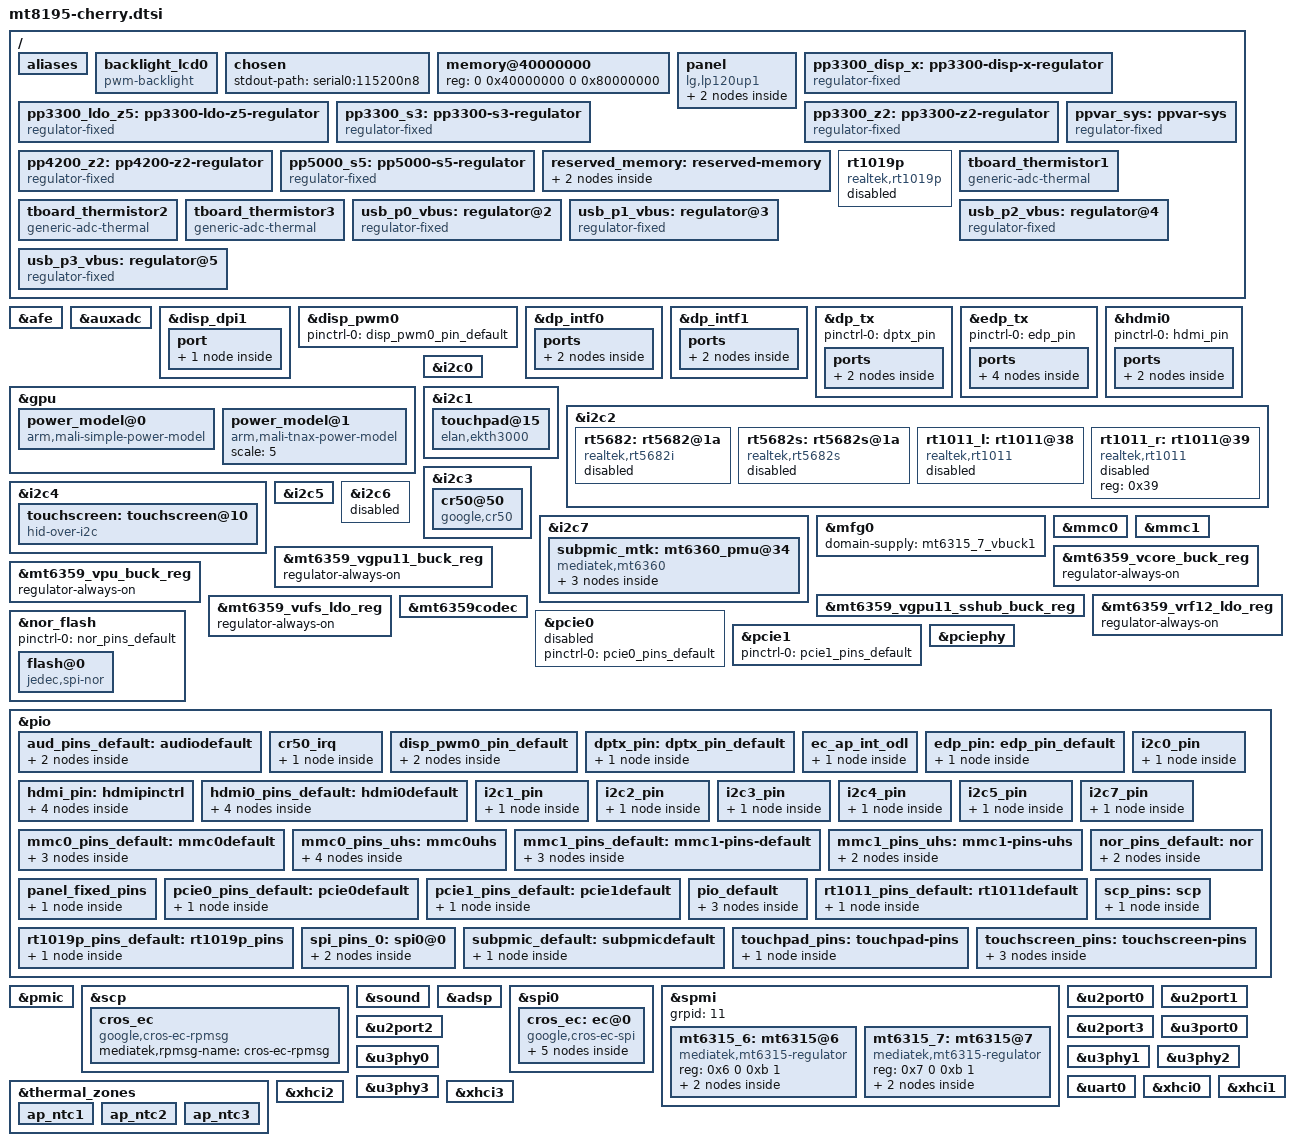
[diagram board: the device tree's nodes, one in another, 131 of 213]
// SPDX-License-Identifier: (GPL-2.0 OR MIT)
/*
 * Copyright (C) 2021 MediaTek Inc.
 */
/dts-v1/;
#include <dt-bindings/gpio/gpio.h>
#include "mt8195.dtsi"
#include "mt6359.dtsi"

/ {
	aliases {
		i2c0 = &i2c0;
		i2c1 = &i2c1;
		i2c2 = &i2c2;
		i2c3 = &i2c3;
		i2c4 = &i2c4;
		i2c5 = &i2c5;
		i2c6 = &i2c6;
		i2c7 = &i2c7;
		mmc0 = &mmc0;
		mmc1 = &mmc1;
		serial0 = &uart0;
	};

	backlight_lcd0: backlight_lcd0 {
		compatible = "pwm-backlight";
		pwms = <&disp_pwm0 0 500000>;
		power-supply = <&ppvar_sys>;
		enable-gpios = <&pio 82 GPIO_ACTIVE_HIGH>;
		brightness-levels = <0 1023>;
		num-interpolated-steps = <1023>;
		default-brightness-level = <576>;
		status = "okay";
	};

	chosen {
		stdout-path = "serial0:115200n8";
	};

	memory@40000000 {
		device_type = "memory";
		reg = <0 0x40000000 0 0x80000000>;
	};

	panel: panel {
		compatible = "lg,lp120up1";
		power-supply = <&pp3300_disp_x>;
		backlight = <&backlight_lcd0>;

		port {
			panel_in: endpoint {
				remote-endpoint = <&edp_out>;
			};
		};
	};

	pp3300_disp_x: pp3300-disp-x-regulator {
		compatible = "regulator-fixed";
		regulator-name = "pp3300_disp_x";
		enable-active-high;
		gpio = <&pio 55 GPIO_ACTIVE_HIGH>;
		pinctrl-names = "default";
		pinctrl-0 = <&panel_fixed_pins>;
		vin-supply = <&pp3300_z2>;
	};

	/* system wide LDO 3.3V power rail */
	pp3300_ldo_z5: pp3300-ldo-z5-regulator {
		compatible = "regulator-fixed";
		regulator-name = "pp3300_ldo_z5";
		regulator-always-on;
		regulator-boot-on;
		regulator-min-microvolt = <3300000>;
		regulator-max-microvolt = <3300000>;
		vin-supply = <&ppvar_sys>;
	};

	/* separately switched 3.3V power rail */
	pp3300_s3: pp3300-s3-regulator {
		compatible = "regulator-fixed";
		regulator-name = "pp3300_s3";
		/* automatically sequenced by PMIC EXT_PMIC_EN2 */
		regulator-always-on;
		regulator-boot-on;
		vin-supply = <&pp3300_z2>;
	};

	/* system wide 3.3V power rail */
	pp3300_z2: pp3300-z2-regulator {
		compatible = "regulator-fixed";
		regulator-name = "pp3300_z2";
		/* EN pin tied to pp4200_z2, which is controlled by EC */
		regulator-always-on;
		regulator-boot-on;
		regulator-min-microvolt = <3300000>;
		regulator-max-microvolt = <3300000>;
		vin-supply = <&ppvar_sys>;
	};

	/* system wide 4.2V power rail */
	pp4200_z2: pp4200-z2-regulator {
		compatible = "regulator-fixed";
		regulator-name = "pp4200_z2";
		/* controlled by EC */
		regulator-always-on;
		regulator-boot-on;
		regulator-min-microvolt = <4200000>;
		regulator-max-microvolt = <4200000>;
		vin-supply = <&ppvar_sys>;
	};

	/* system wide switching 5.0V power rail */
	pp5000_s5: pp5000-s5-regulator {
		compatible = "regulator-fixed";
		regulator-name = "pp5000_s5";
		/* controlled by EC */
		regulator-always-on;
		regulator-boot-on;
		regulator-min-microvolt = <5000000>;
		regulator-max-microvolt = <5000000>;
		vin-supply = <&ppvar_sys>;
	};

	/* system wide semi-regulated power rail from battery or USB */
	ppvar_sys: ppvar-sys {
		compatible = "regulator-fixed";
		regulator-name = "ppvar_sys";
		regulator-always-on;
		regulator-boot-on;
	};

	reserved_memory: reserved-memory {
		#address-cells = <2>;
		#size-cells = <2>;
		ranges;

		scp_mem_reserved: scp_mem_region {
			compatible = "shared-dma-pool";
			reg = <0 0x50000000 0 0x2900000>;
			no-map;
		};

		snd_dma_mem_reserved: snd_dma_mem_region {
			compatible = "shared-dma-pool";
			reg = <0 0x60D80000 0 0x0100000>;
			no-map;
		};
	};

	rt1019p: rt1019p {
		compatible = "realtek,rt1019p";
		pinctrl-names = "default";
		pinctrl-0 = <&rt1019p_pins_default>;
		sdb-gpios = <&pio 100 GPIO_ACTIVE_HIGH>;
		status = "disabled";
	};

	tboard_thermistor1: tboard_thermistor1 {
		compatible = "generic-adc-thermal";
		#thermal-sensor-cells = <0>;
		io-channels = <&auxadc 0>;
		io-channel-names = "sensor-channel";
		temperature-lookup-table = <    (-5000) 1485
                                                0 1406
                                                5000 1317
                                                10000 1219
                                                15000 1115
                                                20000 1007
                                                25000 900
                                                30000 796
                                                35000 697
                                                40000 605
                                                45000 523
                                                50000 449
                                                55000 384
                                                60000 327
                                                65000 279
                                                70000 237
                                                75000 202
                                                80000 172
                                                85000 147
                                                90000 125
                                                95000 107
                                                100000 92
                                                105000 79
                                                110000 68
                                                115000 59
                                                120000 51
                                                125000 44>;
	};

	tboard_thermistor2: tboard_thermistor2 {
		compatible = "generic-adc-thermal";
		#thermal-sensor-cells = <0>;
		io-channels = <&auxadc 0>;
		io-channel-names = "sensor-channel";
		temperature-lookup-table = <    (-5000) 1485
                                                0 1406
                                                5000 1317
                                                10000 1219
                                                15000 1115
                                                20000 1007
                                                25000 900
                                                30000 796
                                                35000 697
                                                40000 605
                                                45000 523
                                                50000 449
                                                55000 384
                                                60000 327
                                                65000 279
                                                70000 237
                                                75000 202
                                                80000 172
                                                85000 147
                                                90000 125
                                                95000 107
                                                100000 92
                                                105000 79
                                                110000 68
                                                115000 59
                                                120000 51
                                                125000 44>;
	};

	tboard_thermistor3: tboard_thermistor3 {
		compatible = "generic-adc-thermal";
		#thermal-sensor-cells = <0>;
		io-channels = <&auxadc 0>;
		io-channel-names = "sensor-channel";
		temperature-lookup-table = <    (-5000) 1485
                                                0 1406
                                                5000 1317
                                                10000 1219
                                                15000 1115
                                                20000 1007
                                                25000 900
                                                30000 796
                                                35000 697
                                                40000 605
                                                45000 523
                                                50000 449
                                                55000 384
                                                60000 327
                                                65000 279
                                                70000 237
                                                75000 202
                                                80000 172
                                                85000 147
                                                90000 125
                                                95000 107
                                                100000 92
                                                105000 79
                                                110000 68
                                                115000 59
                                                120000 51
                                                125000 44>;
	};

	usb_p0_vbus: regulator@2 {
		compatible = "regulator-fixed";
		regulator-name = "vbus0";
		regulator-min-microvolt = <5000000>;
		regulator-max-microvolt = <5000000>;
		enable-active-high;
		regulator-always-on;
	};

	usb_p1_vbus: regulator@3 {
		compatible = "regulator-fixed";
		regulator-name = "vbus1";
		regulator-min-microvolt = <5000000>;
		regulator-max-microvolt = <5000000>;
		enable-active-high;
		regulator-always-on;
	};

	usb_p2_vbus: regulator@4 {
		compatible = "regulator-fixed";
		regulator-name = "vbus2";
		regulator-min-microvolt = <5000000>;
		regulator-max-microvolt = <5000000>;
		enable-active-high;
		regulator-always-on;
	};

	usb_p3_vbus: regulator@5 {
		compatible = "regulator-fixed";
		regulator-name = "vbus3";
		regulator-min-microvolt = <5000000>;
		regulator-max-microvolt = <5000000>;
		enable-active-high;
		regulator-always-on;
	};
};

&afe {
	memory-region = <&snd_dma_mem_reserved>;
	mediatek,etdm-in2-cowork-source = <2>;
	mediatek,etdm-out2-cowork-source = <0>;
	status = "okay";
};

&auxadc {
	status = "okay";
};

&disp_dpi1 {
	port {
		dpi1_out: endpoint@0 {
			remote-endpoint = <&hdmi0_in>;
		};
	};
};

&disp_pwm0 {
	status = "okay";
	pinctrl-names = "default";
	pinctrl-0 = <&disp_pwm0_pin_default>;
};

&dp_intf0 {
	status = "okay";
	ports {
		port {
			dp_intf0_out: endpoint {
				remote-endpoint = <&edp_in>;
			};
		};
	};
};

&dp_intf1 {
	status = "okay";
	ports {
		port {
			dp_intf1_out: endpoint {
				remote-endpoint = <&dptx_in>;
			};
		};
	};
};

&dp_tx {
	pinctrl-names = "default";
	pinctrl-0 = <&dptx_pin>;
	status = "okay";

	ports {
		#address-cells = <1>;
		#size-cells = <0>;
		port@0 {
			reg = <0>;
			dptx_in: endpoint {
			remote-endpoint = <&dp_intf1_out>;
			};
		};
	};
};

&edp_tx {
	pinctrl-names = "default";
	pinctrl-0 = <&edp_pin>;
	status = "okay";

	ports {
		#address-cells = <1>;
		#size-cells = <0>;
		port@0 {
			reg = <0>;
			edp_in: endpoint {
			remote-endpoint = <&dp_intf0_out>;
			};
		};
		port@1 {
			reg = <1>;
			edp_out: endpoint {
				remote-endpoint = <&panel_in>;
			};
		};
	};
};

&gpu {
	supply-names = "mali","mali_sram";
	mali-supply = <&mt6315_7_vbuck1>;
	mali_sram-supply = <&mt6359_vsram_others_ldo_reg>;
	operating-points-v2 = <&gpu_opp_table>;
	power_model@0 {
		compatible = "arm,mali-simple-power-model";
		static-coefficient = <162868>;
		dynamic-coefficient = <2649>;
		ts = <(-199560) 37873 (-665) 9>;
		thermal-zone = "soc_max";
	};
	power_model@1 {
		compatible = "arm,mali-tnax-power-model";
		scale = <5>;
	};
};

&hdmi0 {
	pinctrl-names = "default";
	pinctrl-0 = <&hdmi_pin>;
	ports {
		#address-cells = <1>;
		#size-cells = <0>;
		port@0 {
			reg = <0>;
			hdmi0_in: endpoint {
				remote-endpoint = <&dpi1_out>;
			};
		};
	};
};

&i2c0 {
	clock-frequency = <400000>;
	pinctrl-names = "default";
	pinctrl-0 = <&i2c0_pin>;
};

&i2c1 {
	status = "okay";
	clock-frequency = <400000>;
	pinctrl-names = "default";
	pinctrl-0 = <&i2c1_pin>;
	i2c-scl-internal-delay-ns = <12500>;

	touchpad@15 {
		compatible = "elan,ekth3000";
		reg = <0x15>;

		pinctrl-names = "default";
		pinctrl-0 = <&touchpad_pins>;

		interrupt-parent = <&pio>;
		interrupts = <6 IRQ_TYPE_LEVEL_LOW>;

		vcc-supply = <&pp3300_s3>;

		wakeup-source;
	};
};

&i2c2 {
	status = "okay";
	clock-frequency = <400000>;
	pinctrl-names = "default";
	pinctrl-0 = <&i2c2_pin>;

	rt5682: rt5682@1a {
		compatible = "realtek,rt5682i";
		reg = <0x1a>;
		interrupt-parent = <&pio>;
		interrupts = <89 IRQ_TYPE_EDGE_BOTH>;
		realtek,jd-src = <1>;
		realtek,btndet-delay = <16>;

		AVDD-supply = <&mt6359_vio18_ldo_reg>;
		MICVDD-supply = <&pp3300_z2>;
		VBAT-supply = <&pp3300_ldo_z5>;
		status = "disabled";
	};

	rt5682s: rt5682s@1a {
		compatible = "realtek,rt5682s";
		reg = <0x1a>;
		interrupt-parent = <&pio>;
		interrupts = <89 IRQ_TYPE_EDGE_BOTH>;
		realtek,jd-src = <1>;
		AVDD-supply = <&mt6359_vio18_ldo_reg>;
		MICVDD-supply = <&pp3300_z2>;
		status = "disabled";
	};

	rt1011_l: rt1011@38 {
		compatible = "realtek,rt1011";
		reg = <0x38>;
		pinctrl-names = "default";
		pinctrl-0 = <&rt1011_pins_default>;
		status = "disabled";
	};

	rt1011_r: rt1011@39 {
		compatible = "realtek,rt1011";
		reg = <0x39>;
		status = "disabled";
	};
};

&i2c3 {
	status = "okay";
	clock-frequency = <400000>;
	pinctrl-names = "default";
	pinctrl-0 = <&i2c3_pin>;

	cr50@50 {
		compatible = "google,cr50";
		reg = <0x50>;
		interrupt-parent = <&pio>;
		interrupts = <88 IRQ_TYPE_EDGE_FALLING>;
		pinctrl-names = "default";
		pinctrl-0 = <&cr50_irq>;
	};
};

&i2c4 {
	status = "okay";
	clock-frequency = <400000>;
	pinctrl-names = "default";
	pinctrl-0 = <&i2c4_pin>;

	touchscreen: touchscreen@10 {
		compatible = "hid-over-i2c";
		reg = <0x10>;
		interrupt-parent = <&pio>;
		interrupts = <92 IRQ_TYPE_LEVEL_LOW>;

		pinctrl-names = "default";
		pinctrl-0 = <&touchscreen_pins>;

		post-power-on-delay-ms = <10>;
		hid-descr-addr = <0x0001>;

		vdd-supply = <&pp3300_s3>;
	};
};

&i2c5 {
	status = "okay";
	clock-frequency = <400000>;
	pinctrl-names = "default";
	pinctrl-0 = <&i2c5_pin>;
};

&i2c6 {
	status = "disabled";
};

&i2c7 {
	status = "okay";
	clock-frequency = <400000>;
	pinctrl-names = "default";
	pinctrl-0 = <&i2c7_pin>;

	#address-cells = <1>;
	#size-cells = <0>;

	subpmic_mtk: mt6360_pmu@34 {
		#interrupt-cells = <2>;
		status = "ok";
		compatible = "mediatek,mt6360";
		reg = <0x34>;
		wakeup-source;
		interrupt-controller;

		pinctrl-names = "default";
		pinctrl-0 = <&subpmic_default>;

		interrupt-parent = <&pio>;
		interrupts = <130 IRQ_TYPE_EDGE_FALLING>;
		interrupt-names = "IRQB";

		subpmic_mtk_regulator: regulator {
			compatible = "mediatek,mt6360_ldo";
			mt_pmic_vfp_ldo_reg: ldo1 {
				regulator-compatible = "LDO1";
				regulator-name = "mt6360,ldo1";
				regulator-min-microvolt = <3000000>;
				regulator-max-microvolt = <3600000>;
				regulator-allowed-modes = <0 2>;
				regulator-always-on;
			};
			mt_pmic_vtp_ldo_reg: ldo2 {
				regulator-compatible = "LDO2";
				regulator-name = "vtp";
				regulator-min-microvolt = <1200000>;
				regulator-max-microvolt = <3600000>;
				regulator-allowed-modes = <0 2>;
			};
		};
	};
};

&mfg0 {
	domain-supply = <&mt6315_7_vbuck1>;
};

&mmc0 {
	status = "okay";
	pinctrl-names = "default", "state_uhs";
	pinctrl-0 = <&mmc0_pins_default>;
	pinctrl-1 = <&mmc0_pins_uhs>;
	bus-width = <8>;
	max-frequency = <200000000>;
	cap-mmc-highspeed;
	mmc-hs200-1_8v;
	mmc-hs400-1_8v;
	cap-mmc-hw-reset;
	no-sdio;
	no-sd;
	hs400-ds-delay = <0x14c11>;
	vmmc-supply = <&mt6359_vemc_1_ldo_reg>;
	vqmmc-supply = <&mt6359_vufs_ldo_reg>;
	non-removable;
};

&mmc1 {
	status = "okay";
	pinctrl-names = "default", "state_uhs";
	pinctrl-0 = <&mmc1_pins_default>;
	pinctrl-1 = <&mmc1_pins_uhs>;
	bus-width = <4>;
	max-frequency = <200000000>;
	cap-sd-highspeed;
	sd-uhs-sdr50;
	sd-uhs-sdr104;
	no-mmc;
	no-sdio;
	cd-gpios = <&pio 54 GPIO_ACTIVE_LOW>;
	vmmc-supply = <&mt_pmic_vmch_ldo_reg>;
	vqmmc-supply = <&mt_pmic_vmc_ldo_reg>;
};

/* for CPU-L */
&mt6359_vcore_buck_reg {
	regulator-always-on;
};

/* for CORE */
&mt6359_vgpu11_buck_reg {
	regulator-always-on;
};

&mt6359_vgpu11_sshub_buck_reg {
	regulator-always-on;
	regulator-min-microvolt = <550000>;
	regulator-max-microvolt = <550000>;
};

/* for CORE SRAM */
&mt6359_vpu_buck_reg {
	regulator-always-on;
};

&mt6359_vrf12_ldo_reg {
	regulator-always-on;
};

&mt6359_vufs_ldo_reg {
	regulator-always-on;
};

&mt6359codec {
	mediatek,dmic-mode = <1>; /* one-wire */
	mediatek,mic-type-0 = <2>; /* DMIC */
};

&nor_flash {
	status = "okay";
	pinctrl-names = "default";
	pinctrl-0 = <&nor_pins_default>;

	flash@0 {
		compatible = "jedec,spi-nor";
		reg = <0>;
		spi-max-frequency = <52000000>;
		spi-rx-bus-width = <2>;
		spi-tx-bus-width = <2>;
	};
};

&pcie0 {
	pinctrl-names = "default";
	pinctrl-0 = <&pcie0_pins_default>;
	status = "disabled";
};

&pcie1 {
	pinctrl-names = "default";
	pinctrl-0 = <&pcie1_pins_default>;
	status = "okay";
};

&pciephy {
	status = "okay";
};

&pio {
	pinctrl-names = "default";
	pinctrl-0 = <&pio_default>;

	/* 144 lines */
	gpio-line-names =
		"I2S_SPKR_MCLK",
		"I2S_SPKR_DATAIN",
		"I2S_SPKR_LRCK",
		"I2S_SPKR_BCLK",
		"EC_AP_INT_ODL",
		/*
		 * AP_FLASH_WP_L is crossystem ABI. Schematics
		 * call it AP_FLASH_WP_ODL.
		 */
		"AP_FLASH_WP_L",
		"TCHPAD_INT_ODL",
		"EDP_HPD_1V8",
		"AP_I2C_CAM_SDA",
		"AP_I2C_CAM_SCL",
		"AP_I2C_TCHPAD_SDA_1V8",
		"AP_I2C_TCHPAD_SCL_1V8",
		"AP_I2C_AUD_SDA",
		"AP_I2C_AUD_SCL",
		"AP_I2C_TPM_SDA_1V8",
		"AP_I2C_TPM_SCL_1V8",
		"AP_I2C_TCHSCR_SDA_1V8",
		"AP_I2C_TCHSCR_SCL_1V8",
		"EC_AP_HPD_OD",
		"",
		"PCIE_NVME_RST_L",
		"PCIE_NVME_CLKREQ_ODL",
		"PCIE_RST_1V8_L",
		"PCIE_CLKREQ_1V8_ODL",
		"PCIE_WAKE_1V8_ODL",
		"CLK_24M_CAM0",
		"CAM1_SEN_EN",
		"AP_I2C_PWR_SCL_1V8",
		"AP_I2C_PWR_SDA_1V8",
		"AP_I2C_MISC_SCL",
		"AP_I2C_MISC_SDA",
		"EN_PP5000_HDMI_X",
		"AP_HDMITX_HTPLG",
		"",
		"AP_HDMITX_SCL_1V8",
		"AP_HDMITX_SDA_1V8",
		"AP_RTC_CLK32K",
		"AP_EC_WATCHDOG_L",
		"SRCLKENA0",
		"SRCLKENA1",
		"PWRAP_SPI0_CS_L",
		"PWRAP_SPI0_CK",
		"PWRAP_SPI0_MOSI",
		"PWRAP_SPI0_MISO",
		"SPMI_SCL",
		"SPMI_SDA",
		"",
		"",
		"",
		"I2S_HP_DATAIN",
		"I2S_HP_MCLK",
		"I2S_HP_BCK",
		"I2S_HP_LRCK",
		"I2S_HP_DATAOUT",
		"SD_CD_ODL",
		"EN_PP3300_DISP_X",
		"TCHSCR_RST_1V8_L",
		"TCHSCR_REPORT_DISABLE",
		"EN_PP3300_WLAN_X",
		"BT_KILL_1V8_L",
		"I2S_SPKR_DATAOUT",
		"WIFI_KILL_1V8_L",
		"BEEP_ON",
		"SCP_I2C_SENSOR_SCL_1V8",
		"SCP_I2C_SENSOR_SDA_1V8",
		"",
		"",
		"",
		"",
		"AUD_CLK_MOSI",
		"AUD_SYNC_MOSI",
		"AUD_DAT_MOSI0",
		"AUD_DAT_MOSI1",
		"AUD_DAT_MISO0",
		"AUD_DAT_MISO1",
		"AUD_DAT_MISO2",
		"SCP_VREQ_VAO",
		"AP_SPI_GSC_TPM_CLK",
		"AP_SPI_GSC_TPM_MOSI",
		"AP_SPI_GSC_TPM_CS_L",
		"AP_SPI_GSC_TPM_MISO",
		"EN_PP1000_CAM_X",
		"AP_EDP_BKLTEN",
		"",
		"USB3_HUB_RST_L",
		"",
		"WLAN_ALERT_ODL",
		"EC_IN_RW_ODL",
		"GSC_AP_INT_ODL",
		"HP_INT_ODL",
		"CAM0_RST_L",
		"CAM1_RST_L",
		"TCHSCR_INT_1V8_L",
		"CAM1_DET_L",
		"RST_ALC1011_L",
		"",
		"",
		"BL_PWM_1V8",
		"UART_AP_TX_DBG_RX",
		"UART_DBG_TX_AP_RX",
		"EN_SPKR",
		"AP_EC_WARM_RST_REQ",
		"UART_SCP_TX_DBGCON_RX",
		"UART_DBGCON_TX_SCP_RX",
		"",
		"",
		"KPCOL0",
		"",
		"MT6315_GPU_INT",
		"MT6315_PROC_BC_INT",
		"SD_CMD",
		"SD_CLK",
		"SD_DAT0",
		"SD_DAT1",
		"SD_DAT2",
		"SD_DAT3",
		"EMMC_DAT7",
		"EMMC_DAT6",
		"EMMC_DAT5",
		"EMMC_DAT4",
		"EMMC_RSTB",
		"EMMC_CMD",
		"EMMC_CLK",
		"EMMC_DAT3",
		"EMMC_DAT2",
		"EMMC_DAT1",
		"EMMC_DAT0",
		"EMMC_DSL",
		"",
		"",
		"MT6360_INT_ODL",
		"SCP_JTAG0_TRSTN",
		"AP_SPI_EC_CS_L",
		"AP_SPI_EC_CLK",
		"AP_SPI_EC_MOSI",
		"AP_SPI_EC_MISO",
		"SCP_JTAG0_TMS",
		"SCP_JTAG0_TCK",
		"SCP_JTAG0_TDO",
		"SCP_JTAG0_TDI",
		"AP_SPI_FLASH_CS_L",
		"AP_SPI_FLASH_CLK",
		"AP_SPI_FLASH_MOSI",
		"AP_SPI_FLASH_MISO";

	aud_pins_default: audiodefault {
		pins_cmd_dat {
		    pinmux = <PINMUX_GPIO69__FUNC_AUD_CLK_MOSI>,
			     <PINMUX_GPIO70__FUNC_AUD_SYNC_MOSI>,
			     <PINMUX_GPIO71__FUNC_AUD_DAT_MOSI0>,
			     <PINMUX_GPIO72__FUNC_AUD_DAT_MOSI1>,
			     <PINMUX_GPIO73__FUNC_AUD_DAT_MISO0>,
			     <PINMUX_GPIO74__FUNC_AUD_DAT_MISO1>,
			     <PINMUX_GPIO75__FUNC_AUD_DAT_MISO2>,
			     <PINMUX_GPIO0__FUNC_TDMIN_MCK>,
			     <PINMUX_GPIO1__FUNC_TDMIN_DI>,
			     <PINMUX_GPIO2__FUNC_TDMIN_LRCK>,
			     <PINMUX_GPIO3__FUNC_TDMIN_BCK>,
			     <PINMUX_GPIO60__FUNC_I2SO2_D0>,
			     <PINMUX_GPIO49__FUNC_I2SIN_D0>,
			     <PINMUX_GPIO50__FUNC_I2SO1_MCK>,
			     <PINMUX_GPIO51__FUNC_I2SO1_BCK>,
			     <PINMUX_GPIO52__FUNC_I2SO1_WS>,
			     <PINMUX_GPIO53__FUNC_I2SO1_D0>;
		};

		pins_jack {
			pinmux = <PINMUX_GPIO89__FUNC_GPIO89>;
			input-enable;
			bias-pull-up = <MTK_PUPD_SET_R1R0_01>;
		};
	};

	cr50_irq: cr50_irq {
		pins_bus {
			pinmux = <PINMUX_GPIO88__FUNC_GPIO88>;
			input-enable;
		};
	};

	disp_pwm0_pin_default: disp_pwm0_pin_default {
		pins1 {
			pinmux = <PINMUX_GPIO82__FUNC_GPIO82>;
		};
		pins2 {
			pinmux = <PINMUX_GPIO97__FUNC_DISP_PWM0>;
		};
	};

	dptx_pin: dptx_pin_default {
		pins_cmd_dat1 {
			pinmux = <PINMUX_GPIO18__FUNC_DP_TX_HPD>;
			bias-pull-up;
		};
	};

	ec_ap_int_odl: ec_ap_int_odl {
		pins1 {
			pinmux = <PINMUX_GPIO4__FUNC_GPIO4>;
			input-enable;
			bias-pull-up = <MTK_PUPD_SET_R1R0_01>;
		};
	};

	edp_pin: edp_pin_default {
		pins_cmd_dat {
			pinmux = <PINMUX_GPIO7__FUNC_EDP_TX_HPD>;
			bias-pull-up;
		};
	};

	hdmi_pin: hdmipinctrl {
		hdmi_hotplug {
			pinmux = <PINMUX_GPIO32__FUNC_HDMITX20_HTPLG>;
			bias-disable;
			input-enable;
		};
		hdmi_ddc {
			pinmux = <PINMUX_GPIO34__FUNC_HDMITX20_SCL>,
				 <PINMUX_GPIO35__FUNC_HDMITX20_SDA>;
			mediatek,drive-strength-adv = <0>;
			drive-strength = <MTK_DRIVE_10mA>;
		};
		hdmi_cec {
			pinmux = <PINMUX_GPIO33__FUNC_HDMITX20_CEC>;
			bias-disable;
		};
		hdmi_5vctrl {
			pinmux = <PINMUX_GPIO31__FUNC_GPIO31>;
			slew-rate = <1>;
			output-high;
		};
	};

	hdmi0_pins_default: hdmi0default {
		hdmirx_hpd {
			pinmux = <PINMUX_GPIO27__FUNC_HDMIRX20_HTPLG>;
		};
		hdmirx_5v {
			pinmux = <PINMUX_GPIO28__FUNC_HDMIRX20_PWR5V>;
			bias-disable;
		};
		hdmirx_scl {
			pinmux = <PINMUX_GPIO29__FUNC_HDMIRX20_SCL>;
		};
		hdmirx_sda {
			pinmux = <PINMUX_GPIO30__FUNC_HDMIRX20_SDA>;
			mediatek,drive-strength-adv = <0>;
			drive-strength = <MTK_DRIVE_10mA>;
		};
	};

	i2c0_pin: i2c0_pin {
		pins_bus {
			pinmux = <PINMUX_GPIO8__FUNC_SDA0>,
				 <PINMUX_GPIO9__FUNC_SCL0>;
			bias-disable;
			mediatek,drive-strength-adv = <7>;
		};
	};

	i2c1_pin: i2c1_pin {
		pins_bus {
			pinmux = <PINMUX_GPIO10__FUNC_SDA1>,
				 <PINMUX_GPIO11__FUNC_SCL1>;
			bias-pull-up;
			mediatek,rsel = <7>;
			mediatek,drive-strength-adv = <7>;
		};
	};

	i2c2_pin: i2c2_pin {
		pins_bus {
			pinmux = <PINMUX_GPIO12__FUNC_SDA2>,
				 <PINMUX_GPIO13__FUNC_SCL2>;
			bias-disable;
			mediatek,drive-strength-adv = <7>;
		};
	};

	i2c3_pin: i2c3_pin {
		pins_bus {
			pinmux = <PINMUX_GPIO14__FUNC_SDA3>,
				 <PINMUX_GPIO15__FUNC_SCL3>;
			bias-pull-up;
			mediatek,rsel = <7>;
			mediatek,drive-strength-adv = <7>;
		};
	};

	i2c4_pin: i2c4_pin {
		pins_bus {
			pinmux = <PINMUX_GPIO16__FUNC_SDA4>,
				 <PINMUX_GPIO17__FUNC_SCL4>;
			bias-pull-up;
			mediatek,rsel = <7>;
			mediatek,drive-strength-adv = <0>;
			drive-strength = <MTK_DRIVE_4mA>;
		};
	};

	i2c5_pin: i2c5_pin {
		pins_bus {
			pinmux = <PINMUX_GPIO29__FUNC_SCL5>,
				 <PINMUX_GPIO30__FUNC_SDA5>;
			bias-disable;
			mediatek,drive-strength-adv = <7>;
		};
	};

	i2c7_pin: i2c7_pin {
		pins_bus {
			pinmux = <PINMUX_GPIO27__FUNC_SCL7>,
				 <PINMUX_GPIO28__FUNC_SDA7>;
			bias-disable;
		};
	};

	mmc0_pins_default: mmc0default {
		pins_cmd_dat {
			pinmux = <PINMUX_GPIO126__FUNC_MSDC0_DAT0>,
				 <PINMUX_GPIO125__FUNC_MSDC0_DAT1>,
				 <PINMUX_GPIO124__FUNC_MSDC0_DAT2>,
				 <PINMUX_GPIO123__FUNC_MSDC0_DAT3>,
				 <PINMUX_GPIO119__FUNC_MSDC0_DAT4>,
				 <PINMUX_GPIO118__FUNC_MSDC0_DAT5>,
				 <PINMUX_GPIO117__FUNC_MSDC0_DAT6>,
				 <PINMUX_GPIO116__FUNC_MSDC0_DAT7>,
				 <PINMUX_GPIO121__FUNC_MSDC0_CMD>;
			input-enable;
			drive-strength = <MTK_DRIVE_6mA>;
			bias-pull-up = <MTK_PUPD_SET_R1R0_01>;
		};

		pins_clk {
			pinmux = <PINMUX_GPIO122__FUNC_MSDC0_CLK>;
			drive-strength = <MTK_DRIVE_6mA>;
			bias-pull-down = <MTK_PUPD_SET_R1R0_10>;
		};

		pins_rst {
			pinmux = <PINMUX_GPIO120__FUNC_MSDC0_RSTB>;
			drive-strength = <MTK_DRIVE_6mA>;
			bias-pull-up = <MTK_PUPD_SET_R1R0_01>;
		};
	};

	mmc0_pins_uhs: mmc0uhs{
		pins_cmd_dat {
			pinmux = <PINMUX_GPIO126__FUNC_MSDC0_DAT0>,
				 <PINMUX_GPIO125__FUNC_MSDC0_DAT1>,
				 <PINMUX_GPIO124__FUNC_MSDC0_DAT2>,
				 <PINMUX_GPIO123__FUNC_MSDC0_DAT3>,
				 <PINMUX_GPIO119__FUNC_MSDC0_DAT4>,
				 <PINMUX_GPIO118__FUNC_MSDC0_DAT5>,
				 <PINMUX_GPIO117__FUNC_MSDC0_DAT6>,
				 <PINMUX_GPIO116__FUNC_MSDC0_DAT7>,
				 <PINMUX_GPIO121__FUNC_MSDC0_CMD>;
			input-enable;
			drive-strength = <MTK_DRIVE_8mA>;
			bias-pull-up = <MTK_PUPD_SET_R1R0_01>;
		};

		pins_clk {
			pinmux = <PINMUX_GPIO122__FUNC_MSDC0_CLK>;
			drive-strength = <MTK_DRIVE_8mA>;
			bias-pull-down = <MTK_PUPD_SET_R1R0_10>;
		};

		pins_ds {
			pinmux = <PINMUX_GPIO127__FUNC_MSDC0_DSL>;
			drive-strength = <MTK_DRIVE_8mA>;
			bias-pull-down = <MTK_PUPD_SET_R1R0_10>;
		};

		pins_rst {
			pinmux = <PINMUX_GPIO120__FUNC_MSDC0_RSTB>;
			drive-strength = <MTK_DRIVE_8mA>;
			bias-pull-up = <MTK_PUPD_SET_R1R0_01>;
		};
	};

	mmc1_pins_default: mmc1-pins-default {
		pins_cmd_dat {
			pinmux = <PINMUX_GPIO110__FUNC_MSDC1_CMD>,
				 <PINMUX_GPIO112__FUNC_MSDC1_DAT0>,
				 <PINMUX_GPIO113__FUNC_MSDC1_DAT1>,
				 <PINMUX_GPIO114__FUNC_MSDC1_DAT2>,
				 <PINMUX_GPIO115__FUNC_MSDC1_DAT3>;
			input-enable;
			drive-strength = <MTK_DRIVE_8mA>;
			bias-pull-up = <MTK_PUPD_SET_R1R0_01>;
		};

		pins_clk {
			pinmux = <PINMUX_GPIO111__FUNC_MSDC1_CLK>;
			drive-strength = <MTK_DRIVE_8mA>;
			bias-pull-down = <MTK_PUPD_SET_R1R0_10>;
		};

		pins_insert {
			pinmux = <PINMUX_GPIO54__FUNC_GPIO54>;
			bias-pull-up;
		};
	};

	mmc1_pins_uhs: mmc1-pins-uhs {
		pins_cmd_dat {
			pinmux = <PINMUX_GPIO110__FUNC_MSDC1_CMD>,
				 <PINMUX_GPIO112__FUNC_MSDC1_DAT0>,
				 <PINMUX_GPIO113__FUNC_MSDC1_DAT1>,
				 <PINMUX_GPIO114__FUNC_MSDC1_DAT2>,
				 <PINMUX_GPIO115__FUNC_MSDC1_DAT3>;
			input-enable;
			drive-strength = <MTK_DRIVE_8mA>;
			bias-pull-up = <MTK_PUPD_SET_R1R0_01>;
		};

		pins_clk {
			pinmux = <PINMUX_GPIO111__FUNC_MSDC1_CLK>;
			drive-strength = <MTK_DRIVE_8mA>;
			bias-pull-down = <MTK_PUPD_SET_R1R0_10>;
		};
	};

	nor_pins_default: nor {
		pins0 {
			pinmux = <PINMUX_GPIO142__FUNC_SPINOR_IO0>,
				 <PINMUX_GPIO141__FUNC_SPINOR_CK>,
				 <PINMUX_GPIO143__FUNC_SPINOR_IO1>;
			drive-strength = <MTK_DRIVE_6mA>;
			bias-pull-down;
		};

		pins1 {
			pinmux = <PINMUX_GPIO140__FUNC_SPINOR_CS>;
			drive-strength = <MTK_DRIVE_6mA>;
			bias-pull-up;
		};
	};

	panel_fixed_pins: panel_fixed_pins {
		pins1 {
			pinmux = <PINMUX_GPIO55__FUNC_GPIO55>;
		};
	};

	pcie0_pins_default: pcie0default {
		pins {
			pinmux = <PINMUX_GPIO19__FUNC_WAKEN>,
				 <PINMUX_GPIO20__FUNC_PERSTN>,
				 <PINMUX_GPIO21__FUNC_CLKREQN>;
				 bias-pull-up;
		};
	};

	pcie1_pins_default: pcie1default {
		pins {
			pinmux = <PINMUX_GPIO22__FUNC_PERSTN_1>,
				 <PINMUX_GPIO23__FUNC_CLKREQN_1>,
				 <PINMUX_GPIO24__FUNC_WAKEN_1>;
				 bias-pull-up;
		};
	};

	pio_default: pio_default {
		wifi_enable {
			pinmux = <PINMUX_GPIO58__FUNC_GPIO58>;
			output-high;
			drive-strength = <MTK_DRIVE_14mA>;
		};

		low_power_pu_pd_pins {
			pinmux = <PINMUX_GPIO8__FUNC_GPIO8>,
				 <PINMUX_GPIO9__FUNC_GPIO9>,
				 <PINMUX_GPIO19__FUNC_GPIO19>,
				 <PINMUX_GPIO20__FUNC_GPIO20>,
				 <PINMUX_GPIO21__FUNC_GPIO21>,
				 <PINMUX_GPIO25__FUNC_GPIO25>,
				 <PINMUX_GPIO26__FUNC_GPIO26>,
				 <PINMUX_GPIO46__FUNC_GPIO46>,
				 <PINMUX_GPIO47__FUNC_GPIO47>,
				 <PINMUX_GPIO48__FUNC_GPIO48>,
				 <PINMUX_GPIO65__FUNC_GPIO65>,
				 <PINMUX_GPIO66__FUNC_GPIO66>,
				 <PINMUX_GPIO67__FUNC_GPIO67>,
				 <PINMUX_GPIO68__FUNC_GPIO68>,
				 <PINMUX_GPIO128__FUNC_GPIO128>,
				 <PINMUX_GPIO129__FUNC_GPIO129>;
			input-enable;
			bias-pull-down;
		};

		low_power_pupd_pins {
			pinmux = <PINMUX_GPIO77__FUNC_GPIO77>,
				 <PINMUX_GPIO78__FUNC_GPIO78>,
				 <PINMUX_GPIO79__FUNC_GPIO79>,
				 <PINMUX_GPIO80__FUNC_GPIO80>,
				 <PINMUX_GPIO83__FUNC_GPIO83>,
				 <PINMUX_GPIO85__FUNC_GPIO85>,
				 <PINMUX_GPIO90__FUNC_GPIO90>,
				 <PINMUX_GPIO91__FUNC_GPIO91>,
				 <PINMUX_GPIO93__FUNC_GPIO93>,
				 <PINMUX_GPIO94__FUNC_GPIO94>,
				 <PINMUX_GPIO95__FUNC_GPIO95>,
				 <PINMUX_GPIO96__FUNC_GPIO96>,
				 <PINMUX_GPIO104__FUNC_GPIO104>,
				 <PINMUX_GPIO105__FUNC_GPIO105>,
				 <PINMUX_GPIO107__FUNC_GPIO107>;
			input-enable;
			bias-pull-down = <MTK_PUPD_SET_R1R0_01>;
		};
	};

	rt1011_pins_default: rt1011default {
		pins_spk {
			pinmux = <PINMUX_GPIO94__FUNC_GPIO94>,
			     <PINMUX_GPIO100__FUNC_GPIO100>;
			output-high;
		};
	};

	rt1019p_pins_default: rt1019p_pins {
		pins {
			pinmux = <PINMUX_GPIO100__FUNC_GPIO100>;
			output-low;
		};
	};

	scp_pins: scp {
		pins_scp_vreq {
			pinmux = <PINMUX_GPIO76__FUNC_SCP_VREQ_VAO>;
			bias-disable;
			input-enable;
		};
	};

	spi_pins_0: spi0@0 {
		pins_spi {
			pinmux = <PINMUX_GPIO132__FUNC_SPIM0_CSB>,
				 <PINMUX_GPIO134__FUNC_SPIM0_MO>,
				 <PINMUX_GPIO133__FUNC_SPIM0_CLK>;
			bias-disable;
		};
		pins_spi_mi {
			pinmux = <PINMUX_GPIO135__FUNC_SPIM0_MI>;
			bias-pull-down;
		};
	};

	subpmic_default: subpmicdefault {
		subpmic_pin_irq: pin_irq {
			pinmux = <PINMUX_GPIO130__FUNC_GPIO130>;
			input-enable;
			bias-pull-up;
		};
	};

	touchpad_pins: touchpad-pins {
		touchpad_int {
			pinmux = <PINMUX_GPIO6__FUNC_GPIO6>;
			input-enable;
			bias-pull-up;
		};
	};

	touchscreen_pins: touchscreen-pins {
		pin_irq {
			pinmux = <PINMUX_GPIO92__FUNC_GPIO92>;
			input-enable;
			bias-pull-up = <MTK_PUPD_SET_R1R0_01>;
		};
		touch_pin_reset: pin_reset {
			pinmux = <PINMUX_GPIO56__FUNC_GPIO56>;
			output-high;
		};
		touch_pin_report_sw: pin_report_sw {
			pinmux = <PINMUX_GPIO57__FUNC_GPIO57>;
			output-low;
		};
	};
};

&pmic {
	interrupt-parent = <&pio>;
	interrupts = <222 IRQ_TYPE_LEVEL_HIGH>;
};

&scp {
	memory-region = <&scp_mem_reserved>;
	status = "okay";
	pinctrl-names = "default";
	pinctrl-0 = <&scp_pins>;

	cros_ec {
		compatible = "google,cros-ec-rpmsg";
		mediatek,rpmsg-name = "cros-ec-rpmsg";
	};
};

&sound {
	pinctrl-names = "default";
	pinctrl-0 = <&aud_pins_default>;
	mediatek,adsp = <&adsp>;
	mediatek,dai-link = "DL10_FE", "DPTX_BE", "ETDM1_IN_BE", "ETDM2_IN_BE",
			"ETDM1_OUT_BE", "ETDM2_OUT_BE","UL_SRC1_BE",
			"AFE_SOF_DL2", "AFE_SOF_DL3", "AFE_SOF_UL4", "AFE_SOF_UL5";
	status = "okay";
};

&adsp {
	status = "okay";
};

&spi0 {
	pinctrl-names = "default";
	pinctrl-0 = <&spi_pins_0>;
	mediatek,pad-select = <0>;
	status = "okay";

	cros_ec: ec@0 {
		compatible = "google,cros-ec-spi";
		reg = <0>;
		spi-max-frequency = <3000000>;
		interrupt-parent = <&pio>;
		interrupts = <4 IRQ_TYPE_LEVEL_LOW>;
		pinctrl-names = "default";
		pinctrl-0 = <&ec_ap_int_odl>;

		#address-cells = <1>;
		#size-cells = <0>;

		cros_ec_pwm: ec-pwm {
			compatible = "google,cros-ec-pwm";
			#pwm-cells = <1>;
			status = "disabled";
		};

		i2c_tunnel: i2c-tunnel {
			compatible = "google,cros-ec-i2c-tunnel";
			google,remote-bus = <0>;
			#address-cells = <1>;
			#size-cells = <0>;
		};

		typec {
			compatible = "google,cros-ec-typec";
			#address-cells = <1>;
			#size-cells = <0>;

			usb_c0: connector@0 {
				compatible = "usb-c-connector";
				reg = <0>;
				power-role = "dual";
				data-role = "host";
				try-power-role = "source";
			};

			usb_c1: connector@1 {
				compatible = "usb-c-connector";
				reg = <1>;
				power-role = "dual";
				data-role = "host";
				try-power-role = "source";
			};
		};
	};
};

&spmi {
	#address-cells = <2>;
	#size-cells = <2>;

	grpid = <11>;
	mt6315_6: mt6315@6 {
		compatible = "mediatek,mt6315-regulator";
		reg = <0x6 0 0xb 1>;

		regulators {
			mt6315_6_vbuck1: vbuck1 {
				regulator-compatible = "vbuck1";
				regulator-name = "Vbcpu";
				regulator-min-microvolt = <300000>;
				regulator-max-microvolt = <1193750>;
				regulator-enable-ramp-delay = <256>;
				regulator-allowed-modes = <0 1 2 4>;
				regulator-always-on;
			};
		};
	};

	mt6315_7: mt6315@7 {
		compatible = "mediatek,mt6315-regulator";
		reg = <0x7 0 0xb 1>;

		regulators {
			mt6315_7_vbuck1: vbuck1 {
				regulator-compatible = "vbuck1";
				regulator-name = "Vgpu";
				regulator-min-microvolt = <300000>;
				regulator-max-microvolt = <1193750>;
				regulator-enable-ramp-delay = <256>;
				regulator-allowed-modes = <0 1 2 4>;
			};
		};
	};
};

&thermal_zones {
	ap_ntc1 {
		polling-delay = <1000>; /* milliseconds */
		polling-delay-passive = <0>; /* milliseconds */
		thermal-sensors = <&tboard_thermistor1>;
	};

	ap_ntc2 {
		polling-delay = <1000>; /* milliseconds */
		polling-delay-passive = <0>; /* milliseconds */
		thermal-sensors = <&tboard_thermistor2>;
	};

	ap_ntc3 {
		polling-delay = <1000>; /* milliseconds */
		polling-delay-passive = <0>; /* milliseconds */
		thermal-sensors = <&tboard_thermistor3>;
	};
};

&u2port0 {
	status = "okay";
};

&u2port1 {
	status = "okay";
};

&u2port2 {
	status = "okay";
};

&u2port3 {
	status = "okay";
};

&u3port0 {
	status = "okay";
};

&u3phy0 {
	status="okay";
};

&u3phy1 {
	status = "okay";
};

&u3phy2 {
	status="okay";
};

&u3phy3 {
	status="okay";
};

&uart0 {
	status = "okay";
};

&xhci0 {
	vusb33-supply = <&mt6359_vusb_ldo_reg>;
	vbus-supply = <&usb_p0_vbus>;
	status = "okay";
};

&xhci1 {
	vusb33-supply = <&mt6359_vusb_ldo_reg>;
	vbus-supply = <&usb_p1_vbus>;
	mediatek,frame-cnt;
	status = "okay";
};

&xhci2 {
	vusb33-supply = <&mt6359_vusb_ldo_reg>;
	vbus-supply = <&usb_p2_vbus>;
	mediatek,frame-cnt;
	status = "okay";
};

&xhci3 {
	vusb33-supply = <&mt6359_vusb_ldo_reg>;
	vbus-supply = <&usb_p3_vbus>;
	mediatek,frame-cnt;
	status = "okay";
};

#include <arm/cros-ec-keyboard.dtsi>
#include <arm/cros-ec-sbs.dtsi>
